AUTOSAR XML (schema 00044)
package /COM/VECTOR/CFG/WORKFLOW/SYSDESC/SYNC
  system SYSTEM: category=ECU_EXTRACT
    system mapping MAPPINGS
      data-mappings:
        data-element=COMPOSITIONTYPE.rawCurrentData.rawCurrentData, system-signal=rawCurrentData
        data-element=COMPOSITIONTYPE.DoorStatus.DoorStatus, system-signal=DoorStatus
    root-software-compositions:
      root sw composition prototype COMPOSITIONTYPE: flat-map=FLATMAP, software-composition=COMPOSITIONTYPE
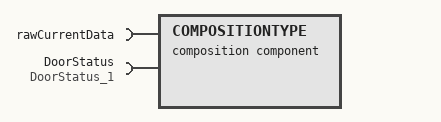
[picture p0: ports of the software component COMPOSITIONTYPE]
  composition sw component type COMPOSITIONTYPE  # UB:Derived from original system description
    require port rawCurrentData: nonqueued-receiver-com-spec{data-element=rawCurrentData, init-value=32768}, required-interface=rawCurrentData
    require port DoorStatus: nonqueued-receiver-com-spec{data-element=DoorStatus, init-value=0}, required-interface=DoorStatus_1
    10 x component:
      BswM: type=BswM
      ComM: type=ComM
      Det: type=Det
      EcuM: type=EcuM
      Os_OsCore0_swc: type=Os_OsCore0_swc
      DemMaster_0: type=DemMaster_0
      DemSatellite_0: type=DemSatellite_0
      Dcm: type=Dcm
      CurrentProcess: type=CurrentProcess
      CurrentProcess2: type=CurrentProcess2
    connect BswM.Switch_ESH_ModeSwitch -> BswM.Notification_ESH_ModeNotification
    connect ComM.UR_CN_CAN00_06ecbb07 -> CpLedTask.UR_CN_CAN00_06ecbb07
    delegate CurrentProcess.DoorStatus <-> outer port DoorStatus  # UB:Derived from original system description
    delegate CurrentProcess.rawCurrentData <-> outer port rawCurrentData  # UB:Derived from original system description
    delegate CurrentProcess2.rawCurrentData <-> outer port rawCurrentData  # UB:Derived from original system description
    delegate CurrentProcess2.DoorStatus <-> outer port DoorStatus  # UB:Derived from original system description
  end to end protection set E2EPROTECTIONSET
  port interface mapping set PORTINTERFACEMAPPINGSET
